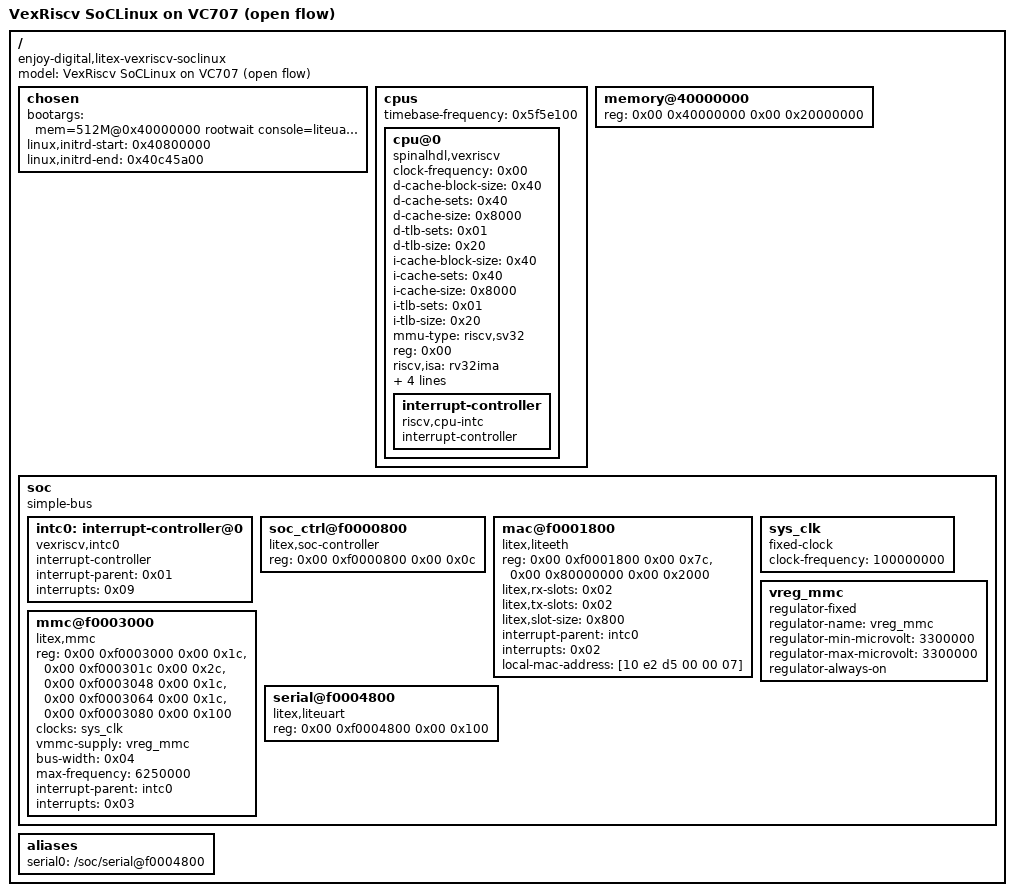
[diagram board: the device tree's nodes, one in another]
/dts-v1/;

/ {
	#address-cells = <0x02>;
	#size-cells = <0x02>;
	compatible = "enjoy-digital,litex-vexriscv-soclinux";
	model = "VexRiscv SoCLinux on VC707 (open flow)";

	chosen {
		bootargs = "mem=512M@0x40000000 rootwait console=liteuart earlycon=sbi root=/dev/ram0 init=/sbin/init swiotlb=32";
		linux,initrd-start = <0x40800000>;
		linux,initrd-end = <0x40c45a00>;
	};

	cpus {
		#address-cells = <0x01>;
		#size-cells = <0x00>;
		timebase-frequency = <0x5f5e100>;

		cpu@0 {
			clock-frequency = <0x00>;
			compatible = "spinalhdl,vexriscv\0sifive,rocket0\0riscv";
			d-cache-block-size = <0x40>;
			d-cache-sets = <0x40>;
			d-cache-size = <0x8000>;
			d-tlb-sets = <0x01>;
			d-tlb-size = <0x20>;
			device_type = "cpu";
			i-cache-block-size = <0x40>;
			i-cache-sets = <0x40>;
			i-cache-size = <0x8000>;
			i-tlb-sets = <0x01>;
			i-tlb-size = <0x20>;
			mmu-type = "riscv,sv32";
			reg = <0x00>;
			riscv,isa = "rv32ima";
			riscv,isa-base = "rv32i";
			riscv,isa-extensions = "i", "m", "a", "zicsr", "zifencei";
			sifive,itim = <0x01>;
			status = "okay";
			tlb-split;

			interrupt-controller {
				#interrupt-cells = <0x01>;
				compatible = "riscv,cpu-intc";
				interrupt-controller;
				phandle = <0x01>;
			};
		};
	};

	memory@40000000 {
		device_type = "memory";
		reg = <0x00 0x40000000 0x00 0x20000000>;
	};

	soc {
		#address-cells = <0x02>;
		#size-cells = <0x02>;
		compatible = "simple-bus";
		ranges;

		intc0: interrupt-controller@0 {
			compatible = "vexriscv,intc0";
			interrupt-controller;
			#interrupt-cells = <0x01>;
			interrupt-parent = <0x01>;
			interrupts = <0x09>;
		};

		soc_ctrl@f0000800 {
			compatible = "litex,soc-controller";
			reg = <0x00 0xf0000800 0x00 0x0c>;
			status = "okay";
		};

		mac@f0001800 {
			compatible = "litex,liteeth";
			reg = <0x00 0xf0001800 0x00 0x7c>,
			      <0x00 0x80000000 0x00 0x2000>;
			reg-names = "mac", "buffer";
			litex,rx-slots = <0x02>;
			litex,tx-slots = <0x02>;
			litex,slot-size = <0x800>;
			interrupt-parent = <&intc0>;
			interrupts = <0x02>;
			local-mac-address = [10 e2 d5 00 00 07];
			status = "okay";
		};

		sys_clk: sys_clk {
			compatible = "fixed-clock";
			#clock-cells = <0x00>;
			clock-frequency = <100000000>;
		};

		vreg_mmc: vreg_mmc {
			compatible = "regulator-fixed";
			regulator-name = "vreg_mmc";
			regulator-min-microvolt = <3300000>;
			regulator-max-microvolt = <3300000>;
			regulator-always-on;
		};

		mmc@f0003000 {
			compatible = "litex,mmc";
			reg = <0x00 0xf0003000 0x00 0x1c>,
			      <0x00 0xf000301c 0x00 0x2c>,
			      <0x00 0xf0003048 0x00 0x1c>,
			      <0x00 0xf0003064 0x00 0x1c>,
			      <0x00 0xf0003080 0x00 0x100>;
			reg-names = "phy", "core", "reader", "writer", "irq";
			clocks = <&sys_clk>;
			vmmc-supply = <&vreg_mmc>;
			bus-width = <0x04>;
			max-frequency = <6250000>;
			interrupt-parent = <&intc0>;
			interrupts = <0x03>;
			status = "okay";
		};

		serial@f0004800 {
			device_type = "serial";
			compatible = "litex,liteuart";
			reg = <0x00 0xf0004800 0x00 0x100>;
			status = "okay";
		};
	};

	aliases {
		serial0 = "/soc/serial@f0004800";
	};
};
